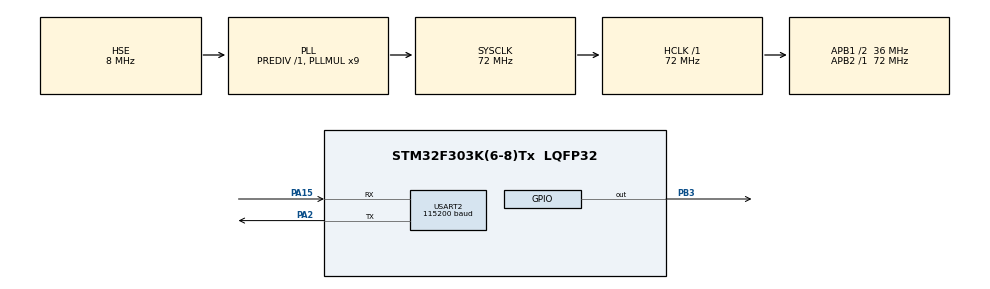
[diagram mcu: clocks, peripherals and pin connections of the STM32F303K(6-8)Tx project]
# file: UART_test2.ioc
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Mcu.Family=STM32F3
Mcu.Name=STM32F303K(6-8)Tx
Mcu.Package=LQFP32
NVIC.PriorityGroup=NVIC_PRIORITYGROUP_4
NVIC.USART2_IRQn=true\:0\:0\:false\:false\:true\:true\:true\:true
PA15.Mode=Asynchronous
PA15.Signal=USART2_RX
PA2.Mode=Asynchronous
PA2.Signal=USART2_TX
PB3.Signal=GPIO_Output
PF0\ /\ OSC_IN.Mode=HSE-External-Clock-Source
PF0\ /\ OSC_IN.Signal=RCC_OSC_IN
ProjectManager.HeapSize=0x200
ProjectManager.StackSize=0x400
ProjectManager.TargetToolchain=STM32CubeIDE
RCC.AHBFreq_Value=72000000
RCC.APB1CLKDivider=RCC_HCLK_DIV2
RCC.APB1Freq_Value=36000000
RCC.APB1TimFreq_Value=72000000
RCC.APB2Freq_Value=72000000
RCC.APB2TimFreq_Value=72000000
RCC.CortexFreq_Value=72000000
RCC.HCLKFreq_Value=72000000
RCC.HSE_VALUE=8000000
RCC.HSI_VALUE=8000000
RCC.PLLMUL=RCC_PLL_MUL9
RCC.PLLSourceVirtual=RCC_PLLSOURCE_HSE
RCC.SYSCLKFreq_VALUE=72000000
RCC.SYSCLKSourceVirtual=RCC_SYSCLKSOURCE_PLLCLK
USART2.BaudRate=115200
USART2.VirtualMode-Asynchronous=VM_ASYNC
board=NUCLEO-F303K8

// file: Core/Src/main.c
/* USER CODE BEGIN Header */
/**
  ******************************************************************************
  * @file           : main.c
  * @brief          : Main program body
  ******************************************************************************
  * @attention
  *
  * Copyright (c) 2022 STMicroelectronics.
  * All rights reserved.
  *
  * This software is licensed under terms that can be found in the LICENSE file
  * in the root directory of this software component.
  * If no LICENSE file comes with this software, it is provided AS-IS.
  *
  ******************************************************************************
  */
/* USER CODE END Header */
#include "main.h"

/* USER CODE BEGIN Includes */
#include<stdio.h>
/* USER CODE END Includes */

 UART_HandleTypeDef huart2;

void SystemClock_Config(void);
static void MX_GPIO_Init(void);
static void MX_USART2_UART_Init(void);

/* USER CODE BEGIN 0 */
char rxbuf[1];
char txbuf1[] = "'a' Key Pressed\r\n";
char txbuf2[] = "'b' Key Pressed\r\n";
char txbuf3[] = "'c' Key Pressed\r\n";
char txbuf4[] = "Other Key Pressed\r\n";

/* USER CODE END 0 */

int main(void)
{

  /* MCU Configuration--------------------------------------------------------*/

  /* Reset of all peripherals, Initializes the Flash interface and the Systick. */
  HAL_Init();

  /* Configure the system clock */
  SystemClock_Config();

  /* Initialize all configured peripherals */
  MX_GPIO_Init();
  MX_USART2_UART_Init();

  /* Infinite loop */
  /* USER CODE BEGIN WHILE */
  while (1)
  {
	  HAL_UART_Receive(&huart2,(uint8_t *)rxbuf, sizeof(rxbuf), 0xF);
	  if (rxbuf[0] != 0){
		  if(rxbuf[0] == 'a'){
			  HAL_UART_Transmit(&huart2,(uint8_t *)txbuf1, sizeof(txbuf1),0xFFFF);
			  HAL_GPIO_WritePin(GPIOB,GPIO_PIN_3,SET);
			  rxbuf[0]=0;
		  }
		  else if(rxbuf[0] == 'b'){
			  HAL_UART_Transmit(&huart2,(uint8_t *)txbuf2, sizeof(txbuf2),0xFFFF);
			  HAL_GPIO_WritePin(GPIOB,GPIO_PIN_3,RESET);
			  rxbuf[0]=0;
		  }
		  else if(rxbuf[0] == 'c'){
			  HAL_UART_Transmit(&huart2,(uint8_t *)txbuf3, sizeof(txbuf3),0xFFFF);
			  HAL_GPIO_WritePin(GPIOB,GPIO_PIN_3,SET);
			  rxbuf[0]=0;
		 		  }
		  else{
			  HAL_UART_Transmit(&huart2,(uint8_t *)txbuf4, sizeof(txbuf4),3000);
			  rxbuf[0]=0;
		  }

	  }

    /* USER CODE END WHILE */

  }
}

void SystemClock_Config(void)
{
  RCC_OscInitTypeDef RCC_OscInitStruct = {0};
  RCC_ClkInitTypeDef RCC_ClkInitStruct = {0};

  /** Initializes the RCC Oscillators according to the specified parameters
  * in the RCC_OscInitTypeDef structure.
  */
  RCC_OscInitStruct.OscillatorType = RCC_OSCILLATORTYPE_HSE;
  RCC_OscInitStruct.HSEState = RCC_HSE_BYPASS;
  RCC_OscInitStruct.HSEPredivValue = RCC_HSE_PREDIV_DIV1;
  RCC_OscInitStruct.HSIState = RCC_HSI_ON;
  RCC_OscInitStruct.PLL.PLLState = RCC_PLL_ON;
  RCC_OscInitStruct.PLL.PLLSource = RCC_PLLSOURCE_HSE;
  RCC_OscInitStruct.PLL.PLLMUL = RCC_PLL_MUL9;
  if (HAL_RCC_OscConfig(&RCC_OscInitStruct) != HAL_OK)
  {
    Error_Handler();
  }

  /** Initializes the CPU, AHB and APB buses clocks
  */
  RCC_ClkInitStruct.ClockType = RCC_CLOCKTYPE_HCLK|RCC_CLOCKTYPE_SYSCLK
                              |RCC_CLOCKTYPE_PCLK1|RCC_CLOCKTYPE_PCLK2;
  RCC_ClkInitStruct.SYSCLKSource = RCC_SYSCLKSOURCE_PLLCLK;
  RCC_ClkInitStruct.AHBCLKDivider = RCC_SYSCLK_DIV1;
  RCC_ClkInitStruct.APB1CLKDivider = RCC_HCLK_DIV2;
  RCC_ClkInitStruct.APB2CLKDivider = RCC_HCLK_DIV1;

  if (HAL_RCC_ClockConfig(&RCC_ClkInitStruct, FLASH_LATENCY_2) != HAL_OK)
  {
    Error_Handler();
  }
}

static void MX_USART2_UART_Init(void)
{

  huart2.Instance = USART2;
  huart2.Init.BaudRate = 115200;
  huart2.Init.WordLength = UART_WORDLENGTH_8B;
  huart2.Init.StopBits = UART_STOPBITS_1;
  huart2.Init.Parity = UART_PARITY_NONE;
  huart2.Init.Mode = UART_MODE_TX_RX;
  huart2.Init.HwFlowCtl = UART_HWCONTROL_NONE;
  huart2.Init.OverSampling = UART_OVERSAMPLING_16;
  huart2.Init.OneBitSampling = UART_ONE_BIT_SAMPLE_DISABLE;
  huart2.AdvancedInit.AdvFeatureInit = UART_ADVFEATURE_NO_INIT;
  if (HAL_UART_Init(&huart2) != HAL_OK)
  {
    Error_Handler();
  }

}

static void MX_GPIO_Init(void)
{
  GPIO_InitTypeDef GPIO_InitStruct = {0};

  /* GPIO Ports Clock Enable */
  __HAL_RCC_GPIOF_CLK_ENABLE();
  __HAL_RCC_GPIOA_CLK_ENABLE();
  __HAL_RCC_GPIOB_CLK_ENABLE();

  /*Configure GPIO pin Output Level */
  HAL_GPIO_WritePin(GPIOB, GPIO_PIN_3, GPIO_PIN_RESET);

  /*Configure GPIO pin : PB3 */
  GPIO_InitStruct.Pin = GPIO_PIN_3;
  GPIO_InitStruct.Mode = GPIO_MODE_OUTPUT_PP;
  GPIO_InitStruct.Pull = GPIO_NOPULL;
  GPIO_InitStruct.Speed = GPIO_SPEED_FREQ_LOW;
  HAL_GPIO_Init(GPIOB, &GPIO_InitStruct);

}

void Error_Handler(void)
{
  __disable_irq();
  while (1)
  {
  }
}
